# nrf5340 register map
Vendor: Nordic Semiconductor; Series: nrf53; File version: 1
CPU: CM33 r0p2, little endian, MPU, FPU, 3 interrupt priority bits
Registers are 32-bit, read-write, reset 0x0 unless marked. A register's access mark holds for its fields unless they carry their own. Offsets are from the block's base; [hi:lo] are bit positions; lines under a group give offsets from that group; 'fields as' and 'values as' point back to an identical list.

## CLOCK_NS — Clock Management 0
Base 0x40005000
Same registers: CLOCK_S 0x50005000
0x00 TASKS_HFCLKSTART wo — Start HFCLK crystal oscillator
  [0] TASKS_HFCLKSTART
    1=Trigger task
0x04 TASKS_HFCLKSTOP wo — Stop HFCLK crystal oscillator
  [0] TASKS_HFCLKSTOP
    1=Trigger task
0x08 TASKS_LFCLKSTART wo — Start LFCLK source
  [0] TASKS_LFCLKSTART
    1=Trigger task
0x0C TASKS_LFCLKSTOP wo — Stop LFCLK source
  [0] TASKS_LFCLKSTOP
    1=Trigger task
0x10 TASKS_CAL wo — Start RCOSC32k calibration
  [0] TASKS_CAL
    1=Trigger task
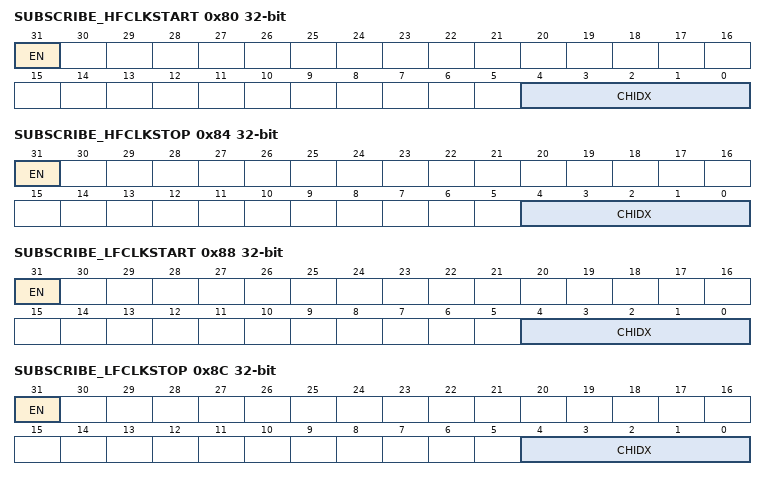
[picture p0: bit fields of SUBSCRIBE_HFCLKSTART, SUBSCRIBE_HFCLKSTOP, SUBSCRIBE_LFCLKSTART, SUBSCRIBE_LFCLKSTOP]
0x80 SUBSCRIBE_HFCLKSTART — Subscribe configuration for task HFCLKSTART
  [31] EN
    0=Disabled (Disable subscription); 1=Enabled (Enable subscription)
  [4:0] CHIDX — Channel that task HFCLKSTART will subscribe to
0x84 SUBSCRIBE_HFCLKSTOP — Subscribe configuration for task HFCLKSTOP
  [31] EN
    values as SUBSCRIBE_HFCLKSTART.EN
  [4:0] CHIDX — Channel that task HFCLKSTOP will subscribe to
0x88 SUBSCRIBE_LFCLKSTART — Subscribe configuration for task LFCLKSTART
  [31] EN
    values as SUBSCRIBE_HFCLKSTART.EN
  [4:0] CHIDX — Channel that task LFCLKSTART will subscribe to
0x8C SUBSCRIBE_LFCLKSTOP — Subscribe configuration for task LFCLKSTOP
  [31] EN
    values as SUBSCRIBE_HFCLKSTART.EN
  [4:0] CHIDX — Channel that task LFCLKSTOP will subscribe to
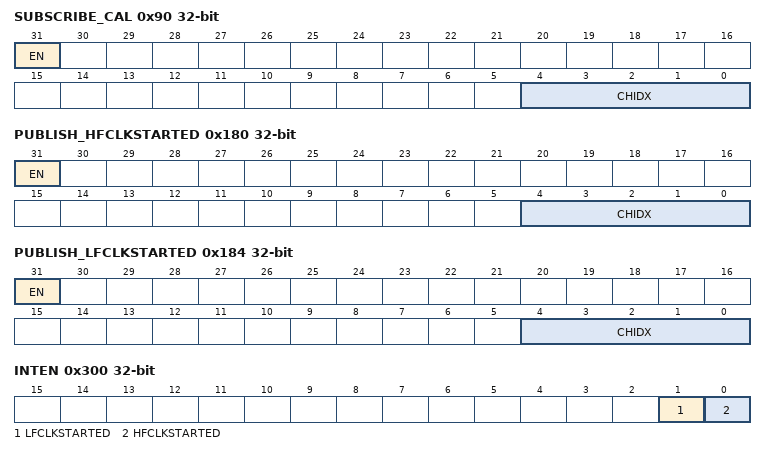
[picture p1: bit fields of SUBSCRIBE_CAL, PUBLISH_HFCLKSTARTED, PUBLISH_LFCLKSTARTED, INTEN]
0x90 SUBSCRIBE_CAL — Subscribe configuration for task CAL
  [31] EN
    values as SUBSCRIBE_HFCLKSTART.EN
  [4:0] CHIDX — Channel that task CAL will subscribe to
0x100 EVENTS_HFCLKSTARTED — HFCLK oscillator started
  [0] EVENTS_HFCLKSTARTED
    0=NotGenerated (Event not generated); 1=Generated (Event generated)
0x104 EVENTS_LFCLKSTARTED — LFCLK started
  [0] EVENTS_LFCLKSTARTED
    values as EVENTS_HFCLKSTARTED.EVENTS_HFCLKSTARTED
0x180 PUBLISH_HFCLKSTARTED — Publish configuration for event HFCLKSTARTED
  [31] EN
    0=Disabled (Disable publishing); 1=Enabled (Enable publishing)
  [4:0] CHIDX — Channel that event HFCLKSTARTED will publish to.
0x184 PUBLISH_LFCLKSTARTED — Publish configuration for event LFCLKSTARTED
  [31] EN
    values as PUBLISH_HFCLKSTARTED.EN
  [4:0] CHIDX — Channel that event LFCLKSTARTED will publish to.
0x300 INTEN — Enable or disable interrupt
  [1] LFCLKSTARTED — Enable or disable interrupt for event LFCLKSTARTED
    0=Disabled; 1=Enabled
  [0] HFCLKSTARTED — Enable or disable interrupt for event HFCLKSTARTED
    0=Disabled; 1=Enabled
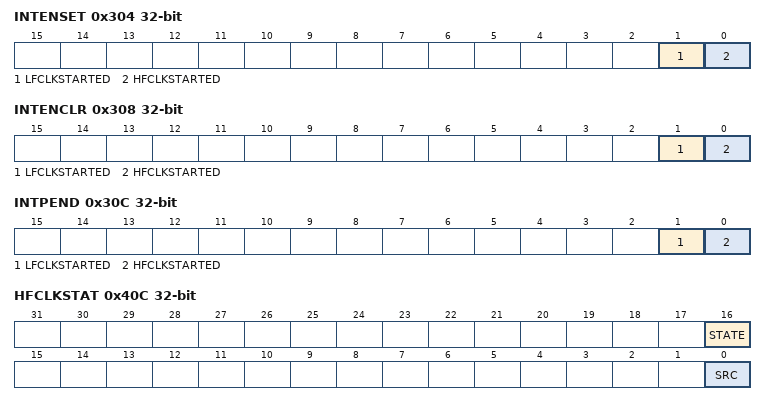
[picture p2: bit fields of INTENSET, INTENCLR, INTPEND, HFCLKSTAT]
0x304 INTENSET — Enable interrupt
  [1] LFCLKSTARTED — Write '1' to enable interrupt for event LFCLKSTARTED
    on read: 0=Disabled (Read: Disabled); 1=Enabled (Read: Enabled) | on write: 1=Set (Enable)
  [0] HFCLKSTARTED — Write '1' to enable interrupt for event HFCLKSTARTED
    values as LFCLKSTARTED
0x308 INTENCLR — Disable interrupt
  [1] LFCLKSTARTED — Write '1' to disable interrupt for event LFCLKSTARTED
    on read: 0=Disabled (Read: Disabled); 1=Enabled (Read: Enabled) | on write: 1=Clear (Disable)
  [0] HFCLKSTARTED — Write '1' to disable interrupt for event HFCLKSTARTED
    values as LFCLKSTARTED
0x30C INTPEND ro — Pending interrupts
  [1] LFCLKSTARTED — Read pending status of interrupt for event LFCLKSTARTED
    on read: 0=NotPending (Read: Not pending); 1=Pending (Read: Pending)
  [0] HFCLKSTARTED — Read pending status of interrupt for event HFCLKSTARTED
    values as LFCLKSTARTED
0x408 HFCLKRUN ro — Status indicating that HFCLKSTART task has been triggered
  [0] STATUS — HFCLKSTART task triggered or not
    0=NotTriggered (Task not triggered); 1=Triggered (Task triggered)
0x40C HFCLKSTAT ro — Which HFCLK source is running
  [16] STATE — HFCLK state
    0=NotRunning (HFCLK not running); 1=Running (HFCLK running)
  [0] SRC — Active clock source
    0=HFINT (HFCLK clock source: HFINT - 128 MHz on-chip oscillator); 1=HFXO (HFCLK clock source: HFXO - 128 MHz clock derived from external 32 MHz crystal oscillator)
0x414 LFCLKRUN ro — Status indicating that LFCLKSTART task has been triggered
  [0] STATUS — LFCLKSTART task triggered or not
    values as HFCLKRUN.STATUS
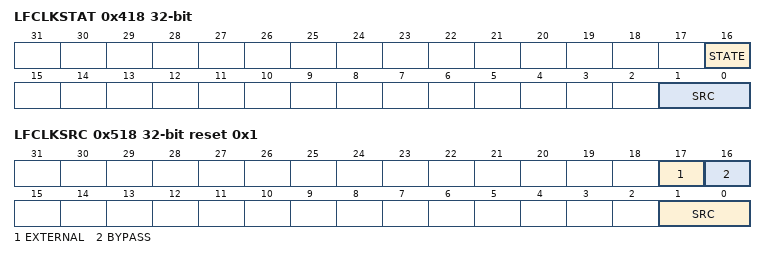
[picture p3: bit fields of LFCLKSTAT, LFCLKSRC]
0x418 LFCLKSTAT ro — Which LFCLK source is running
  [16] STATE — LFCLK state
    0=NotRunning (LFCLK not running); 1=Running (LFCLK running)
  [1:0] SRC — Active clock source
    0=LFULP (32.768 kHz ultra low power RC oscillator); 1=LFRC (32.768 kHz RC oscillator); 2=LFXO (32.768 kHz crystal oscillator); 3=LFSYNT (32.768 kHz synthesized from HFCLK)
0x41C LFCLKSRCCOPY ro — Copy of LFCLKSRC register, set when LFCLKSTART task was triggered
  [1:0] SRC — Clock source
    values as LFCLKSTAT.SRC
0x430 HFCLKCURRFREQ — Current frequency of HFCLK
  [1:0] HFCLKCURRFREQ — Current High frequency clock (HCLK) frequency
    0=Div1 (HFCLK divided by 1); 1=Div2 (HFCLK divided by 2); 2=Div4 (HFCLK divided by 4); 3=Div8 (HFCLK divided by 8)
0x514 HFCLKSRC reset 0x1 — Clock source for the HFCLK oscillator, and configuration of XTAL oscillator. This register shall only be written while no oscillation is present on XC1. Failing to do so may cause unexpected behaviour.
  [0] SRC — Select which HFCLK source is started by the START task
    0=HFINT (HFCLKSTART task starts HFINT oscillator); 1=HFXO (HFCLKSTART task starts HFXO oscillator)
0x518 LFCLKSRC reset 0x1 — Clock source for the LFCLK. LFCLKSTART task starts starts a clock source selected with this register.
  [17] EXTERNAL — Enable or disable external source for LFCLK
    0=Disabled (Disable external source (use with Xtal)); 1=Enabled (Enable use of external source instead of Xtal (SRC needs to be set to Xtal))
  [16] BYPASS — Enable or disable bypass of LFCLK crystal oscillator with external clock source
    0=Disabled (Disable (use with Xtal or low-swing external source)); 1=Enabled (Enable (use with rail-to-rail external source))
  [1:0] SRC — Clock source
    values as LFCLKSTAT.SRC
0x558 HFCLKCTRL — HFCLK frequency configuration.
  [1:0] HCLK — High frequency clock HCLK
    0=Div1 (Divide HFCLK by 1); 1=Div2 (Divide HFCLK by 2); 2=Div4 (Divide HFCLK by 4); 3=Div8 (Divide HFCLK by 8)
0x55C HFCLKAUDIO group — Unspecified
  0x00 FREQUENCY — Audio PLL Frequency from 10.666MHz to 13.333MHz in 3.3ppm steps
    [15:0] FREQUENCY — Frequency 0: 10.666 MHz 65535: 13.333 MHz
  0x04 FREQINC — Frequency increment
    [7:0] FREQINC — Signed 8-bit frequency increment, applied to FREQUENCY every FREQINCPERIOD.
  0x08 FREQINCPERIOD — Frequency increment period 1us steps
    [15:0] FREQINCPERIOD — 0: Invalid 1: 1 us period 65535: 65535 us period
  0x0C FREQINCENABLE — Frequency increment enable
    [0] FREQINCENABLE
      0=Disabled (Disable frequency incrementation); 1=Enabled (Enable frequency incrementation)
